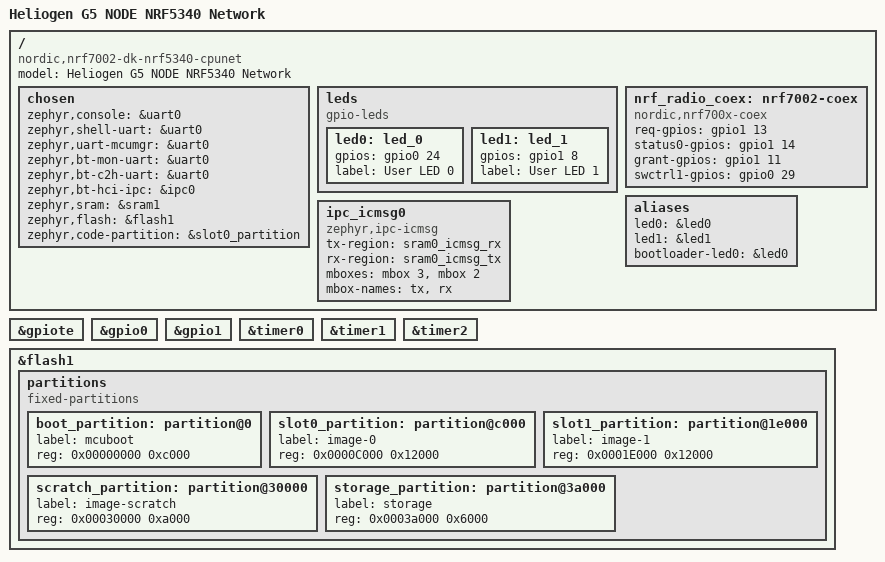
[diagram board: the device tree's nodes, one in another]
/*
 * Copyright (c) 2022 Nordic Semiconductor ASA
 *
 * SPDX-License-Identifier: LicenseRef-Nordic-5-Clause
 */

/dts-v1/;
#include <nordic/nrf5340_cpunet_qkaa.dtsi>
#include "heliogen_g5_node_nrf5340_cpunet-pinctrl.dtsi"

/ {
	model = "Heliogen G5 NODE NRF5340 Network";
	compatible = "nordic,nrf7002-dk-nrf5340-cpunet";

	chosen {
		zephyr,console = &uart0;
		zephyr,shell-uart = &uart0;
		zephyr,uart-mcumgr = &uart0;
		zephyr,bt-mon-uart = &uart0;
		zephyr,bt-c2h-uart = &uart0;
		zephyr,bt-hci-ipc = &ipc0;
		zephyr,sram = &sram1;
		zephyr,flash = &flash1;
		zephyr,code-partition = &slot0_partition;
	};

	leds {
		compatible = "gpio-leds";
		led0: led_0 {
			gpios = <&gpio0 24 GPIO_ACTIVE_HIGH>;
			label = "User LED 0";
		};
		led1: led_1 {
			gpios = <&gpio1 8 GPIO_ACTIVE_HIGH>;
			label = "User LED 1";
		};
	};
	/*
	buttons {
		compatible = "gpio-keys";
		button0: button_0 {
			gpios = <&gpio1 8 (GPIO_PULL_UP | GPIO_ACTIVE_LOW)>;
			label = "Push button 1";
		};
		button1: button_1 {
			gpios = <&gpio1 9 (GPIO_PULL_UP | GPIO_ACTIVE_LOW)>;
			label = "Push button 2";
		};
	};
	*/

	/*
	DK definitions
	nrf_radio_coex: nrf7002-coex {
		status = "okay";
		compatible = "nordic,nrf700x-coex";
		req-gpios = <&gpio0 28 GPIO_ACTIVE_HIGH>;
		status0-gpios = <&gpio0 30 GPIO_ACTIVE_HIGH>;
		grant-gpios = <&gpio0 24 GPIO_ACTIVE_HIGH>;
		swctrl1-gpios = <&gpio0 29 GPIO_ACTIVE_HIGH>;
	};
	*/
	/* G5 definitions - this pins are not actually connected to the 7002*/
	nrf_radio_coex: nrf7002-coex {
		status = "okay";
		compatible = "nordic,nrf700x-coex";
		req-gpios = <&gpio1 13 GPIO_ACTIVE_HIGH>;
		status0-gpios = <&gpio1 14 GPIO_ACTIVE_HIGH>;
		grant-gpios = <&gpio1 11 GPIO_ACTIVE_HIGH>;
		swctrl1-gpios = <&gpio0 29 GPIO_ACTIVE_HIGH>;
	};

	/* These aliases are provided for compatibility with samples */
	aliases {
		led0 = &led0;
		led1 = &led1;
		bootloader-led0 = &led0;
	};

};

&gpiote {
	status = "okay";
};

&gpio0 {
	status = "okay";
};

&gpio1 {
	status = "okay";
};


&timer0 {
	status = "okay";
};

&timer1 {
	status = "okay";
};

&timer2 {
	status = "okay";
};

&flash1 {

	partitions {
		compatible = "fixed-partitions";
		#address-cells = <1>;
		#size-cells = <1>;

		boot_partition: partition@0 {
			label = "mcuboot";
			reg = <0x00000000 0xc000>;
		};
		slot0_partition: partition@c000 {
			label = "image-0";
			reg = <0x0000C000 0x12000>;
		};
		slot1_partition: partition@1e000 {
			label = "image-1";
			reg = <0x0001E000 0x12000>;
		};
		scratch_partition: partition@30000 {
			label = "image-scratch";
			reg = <0x00030000 0xa000>;
		};
		storage_partition: partition@3a000 {
			label = "storage";
			reg = <0x0003a000 0x6000>;
		};
	};
};

/*
 * Extra IPC channel for custom NET<->APP communication (ICMsg backend).
 *
 * This instance is independent of the default OpenAMP/static-vrings instance
 * (ipc0). The shared SRAM regions are defined in
 * nrf5340_shared_sram_planning_conf.dts.
 *
 * IMPORTANT: compared to the APP core, tx/rx regions and MBOX channels are
 * swapped, as required by the ICMsg backend.
 */
/ {
	ipc_icmsg0: ipc_icmsg0 {
		compatible = "zephyr,ipc-icmsg";
		/* Swap tx/rx relative to CPUAPP */
		tx-region = <&sram0_icmsg_rx>;
		rx-region = <&sram0_icmsg_tx>;
		/* Swap channels relative to CPUAPP */
		mboxes = <&mbox 3>, <&mbox 2>;
		mbox-names = "tx", "rx";
		status = "okay";
	};
};

/* Include shared RAM configuration file */
#include "nrf5340_shared_sram_planning_conf.dts"
